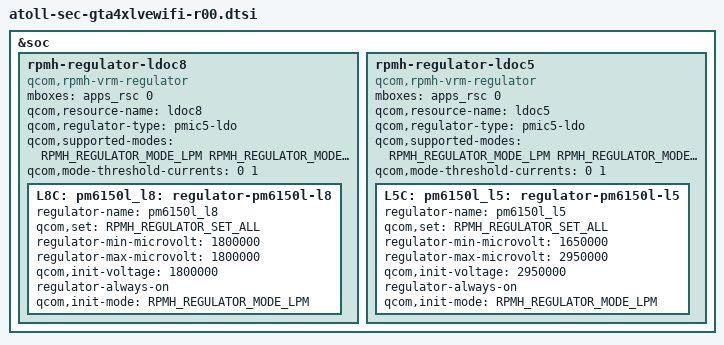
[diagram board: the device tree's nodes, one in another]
/* Copyright (c) 2020, The Linux Foundation. All rights reserved.
 *
 * This program is free software; you can redistribute it and/or modify
 * it under the terms of the GNU General Public License version 2 and
 * only version 2 as published by the Free Software Foundation.
 *
 * This program is distributed in the hope that it will be useful,
 * but WITHOUT ANY WARRANTY; without even the implied warranty of
 * MERCHANTABILITY or FITNESS FOR A PARTICULAR PURPOSE.  See the
 * GNU General Public License for more details.
 */

#include "atoll-sec-gta4xlve-common.dtsi"
#include "atoll-sec-gta4xlve-pinctrl-r00.dtsi"
#include "atoll-sec-gta4xlvewifi-pm-common.dtsi"
#include "atoll-sec-gta4xlve-display-r00.dtsi"
#include "atoll-sec-gta4xlve-input-common.dtsi"
#include "../drivers/atoll-sec-gta4xlve-audio-common.dtsi"
#include "../drivers/atoll-sec-gta4xlve-battery-common.dtsi"
#include "../drivers/atoll-sec-gta4xlvewifi-usb-r00.dtsi"
#include <dt-bindings/regulator/qcom,rpmh-regulator.h>

&soc {
	//Sensor Vdd
	rpmh-regulator-ldoc8 {
		compatible = "qcom,rpmh-vrm-regulator";
		mboxes = <&apps_rsc 0>;
		qcom,resource-name = "ldoc8";
		qcom,regulator-type = "pmic5-ldo";
		qcom,supported-modes =
			<RPMH_REGULATOR_MODE_LPM
			RPMH_REGULATOR_MODE_HPM>;
		qcom,mode-threshold-currents = <0 1>;
		L8C:
		pm6150l_l8: regulator-pm6150l-l8 {
			regulator-name = "pm6150l_l8";
			qcom,set = <RPMH_REGULATOR_SET_ALL>;
			regulator-min-microvolt = <1800000>;
			regulator-max-microvolt = <1800000>;
			qcom,init-voltage = <1800000>;
			regulator-always-on;
			qcom,init-mode =
				<RPMH_REGULATOR_MODE_LPM>;
		};
	};

	rpmh-regulator-ldoc5 {
		compatible = "qcom,rpmh-vrm-regulator";
		mboxes = <&apps_rsc 0>;
		qcom,resource-name = "ldoc5";
		qcom,regulator-type = "pmic5-ldo";
		qcom,supported-modes =
				<RPMH_REGULATOR_MODE_LPM
				RPMH_REGULATOR_MODE_HPM>;
		qcom,mode-threshold-currents = <0 1>;
		L5C: pm6150l_l5: regulator-pm6150l-l5 {
			regulator-name = "pm6150l_l5";
			qcom,set = <RPMH_REGULATOR_SET_ALL>;
			regulator-min-microvolt = <1650000>;
			regulator-max-microvolt = <2950000>;
			qcom,init-voltage = <2950000>;
			regulator-always-on;
			qcom,init-mode = <RPMH_REGULATOR_MODE_LPM>;
		};
	};

};
